# SMS_LITE_WDTCTRL_0_SMS_LITE_TIFS_RTI_MMR_44135100h register map
Vendor: Texas Instruments
Peripheral module from a debugger description file (folder am62L).
Registers are 32-bit, read-write, reset 0x0 unless marked. A register's access mark holds for its fields unless they carry their own. Offsets are as the file gives them; lines under a group give offsets from that group; [hi:lo] are bit positions; {n}, {i} and the like mark numbered series; 'fields as' and 'values as' point back to an identical list; <NAME> marks a mode.

## SMS_LITE_TIFS_RTI_MMR
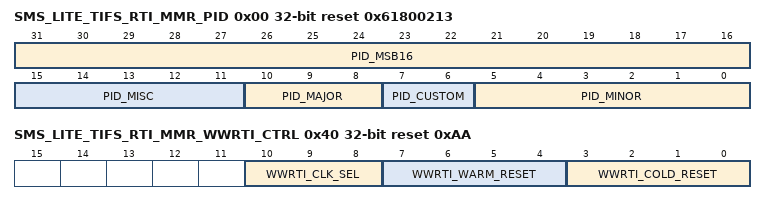
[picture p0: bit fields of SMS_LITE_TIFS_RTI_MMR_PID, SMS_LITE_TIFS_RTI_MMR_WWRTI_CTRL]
0x00 SMS_LITE_TIFS_RTI_MMR_PID ro reset 0x61800213
  [31:16] PID_MSB16 — Reset Source: mod_g_rst_n
  [15:11] PID_MISC — Reset Source: mod_g_rst_n
  [10:8] PID_MAJOR — Reset Source: mod_g_rst_n
  [7:6] PID_CUSTOM — Reset Source: mod_g_rst_n
  [5:0] PID_MINOR — Reset Source: mod_g_rst_n
0x20 SMS_LITE_TIFS_RTI_MMR_LOCK0_KICK0
  [31:0] LOCK0_KICK0 — - KICK0 component Reset Source: mod_g_rst_n
0x24 SMS_LITE_TIFS_RTI_MMR_LOCK0_KICK1
  [31:0] LOCK0_KICK1 — - KICK1 component Reset Source: mod_g_rst_n
0x40 SMS_LITE_TIFS_RTI_MMR_WWRTI_CTRL reset 0xAA
  [10:8] WWRTI_CLK_SEL — Reset Source: mod_por_rst_n
  [7:4] WWRTI_WARM_RESET — Reset Source: mod_por_rst_n
  [3:0] WWRTI_COLD_RESET — Reset Source: mod_por_rst_n
0x50 SMS_LITE_TIFS_RTI_MMR_WWRTI_CLOCK_CTRL reset 0xA
  [3:0] WWRTI_CLK_CTRL — Reset Source: mod_por_rst_n
